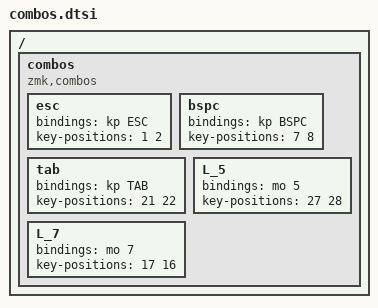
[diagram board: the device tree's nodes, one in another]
/ {
    combos {
        compatible = "zmk,combos";

        esc {
            bindings = <&kp ESC>;
            key-positions = <1 2>;
        };

        bspc {
            bindings = <&kp BSPC>;
            key-positions = <7 8>;
        };

        tab {
            bindings = <&kp TAB>;
            key-positions = <21 22>;
        };

        L_5 {
            bindings = <&mo 5>;
            key-positions = <27 28>;
        };
        L_7 {
            bindings = <&mo 7>;
            key-positions = <17 16>;
        };
    };
};
